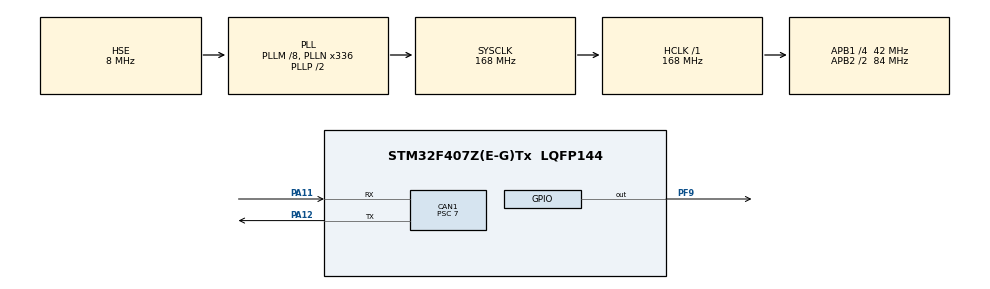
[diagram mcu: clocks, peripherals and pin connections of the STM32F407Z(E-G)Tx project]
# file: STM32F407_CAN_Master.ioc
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CAN1.BS1=CAN_BS1_7TQ
CAN1.BS2=CAN_BS2_4TQ
CAN1.CalculateBaudRate=499999
CAN1.CalculateTimeBit=2000
CAN1.CalculateTimeQuantum=166.66666666666669
CAN1.Prescaler=7
Mcu.Family=STM32F4
Mcu.Name=STM32F407Z(E-G)Tx
Mcu.Package=LQFP144
NVIC.CAN1_RX0_IRQn=true\:0\:0\:false\:false\:true\:true\:true\:true
NVIC.PriorityGroup=NVIC_PRIORITYGROUP_4
PA11.Mode=CAN_Activate
PA11.Signal=CAN1_RX
PA12.Mode=CAN_Activate
PA12.Signal=CAN1_TX
PA13.Mode=Serial_Wire
PA13.Signal=SYS_JTMS-SWDIO
PA14.Mode=Serial_Wire
PA14.Signal=SYS_JTCK-SWCLK
PF9.PinState=GPIO_PIN_SET
PF9.Signal=GPIO_Output
PH0-OSC_IN.Mode=HSE-External-Oscillator
PH0-OSC_IN.Signal=RCC_OSC_IN
PH1-OSC_OUT.Mode=HSE-External-Oscillator
PH1-OSC_OUT.Signal=RCC_OSC_OUT
ProjectManager.HeapSize=0x200
ProjectManager.StackSize=0x400
ProjectManager.TargetToolchain=MDK-ARM V5.32
RCC.48MHZClocksFreq_Value=84000000
RCC.AHBFreq_Value=168000000
RCC.APB1CLKDivider=RCC_HCLK_DIV4
RCC.APB1Freq_Value=42000000
RCC.APB1TimFreq_Value=84000000
RCC.APB2CLKDivider=RCC_HCLK_DIV2
RCC.APB2Freq_Value=84000000
RCC.APB2TimFreq_Value=168000000
RCC.CortexFreq_Value=168000000
RCC.HCLKFreq_Value=168000000
RCC.HSE_VALUE=8000000
RCC.HSI_VALUE=16000000
RCC.LSE_VALUE=32768
RCC.PLLM=8
RCC.PLLN=336
RCC.PLLSourceVirtual=RCC_PLLSOURCE_HSE
RCC.SYSCLKFreq_VALUE=168000000
RCC.SYSCLKSource=RCC_SYSCLKSOURCE_PLLCLK
RCC.VCOOutputFreq_Value=336000000
board=custom

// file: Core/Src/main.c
/* USER CODE BEGIN Header */
/**
  ******************************************************************************
  * @file           : main.c
  * @brief          : Main program body
  ******************************************************************************
  * @attention
  *
  * Copyright (c) 2026 STMicroelectronics.
  * All rights reserved.
  *
  * This software is licensed under terms that can be found in the LICENSE file
  * in the root directory of this software component.
  * If no LICENSE file comes with this software, it is provided AS-IS.
  *
  ******************************************************************************
  */
/* USER CODE END Header */
#include "main.h"
#include "can.h"
#include "gpio.h"
/* USER CODE BEGIN Includes */
#include "CO_driver.h"
#include "CANopen.h"
#include "OD.h"
/* USER CODE END Includes */

/* USER CODE BEGIN PV */
CO_t* CO = NULL;
/* USER CODE END PV */

void SystemClock_Config(void);

int main(void)
{

  /* MCU Configuration--------------------------------------------------------*/

  /* Reset of all peripherals, Initializes the Flash interface and the Systick. */
  HAL_Init();

  /* Configure the system clock */
  SystemClock_Config();

  /* Initialize all configured peripherals */
  MX_GPIO_Init();
  MX_CAN1_Init();
  /* USER CODE BEGIN 2 */
  HAL_CAN_Start(&hcan1); /* 启动CAN：退出初始化模式，进入正常模式 */
  /* USER CODE END 2 */

  /* Infinite loop */
  while (1)
  {

    /* USER CODE BEGIN 3 */

  /* 暂时不跑 CANopen，改用裸 CAN 发目标位置给 F103 */
  static uint32_t master_target = 16384;  // 第一个目标：90 度
  static uint32_t last_switch = 0;

  /* 每 3 秒切换目标，切换时只发一次（避免反复发打断 F103 定位） */
  if (HAL_GetTick() - last_switch > 3000) {
      last_switch = HAL_GetTick();
      master_target = (master_target == 16384) ? 32768 : 16384;

      uint8_t pos_data[4];
      pos_data[0] = (master_target >> 24) & 0xFF;  // 大端
      pos_data[1] = (master_target >> 16) & 0xFF;
      pos_data[2] = (master_target >> 8) & 0xFF;
      pos_data[3] = master_target & 0xFF;

      CAN_TxHeaderTypeDef tx_header;
      tx_header.StdId = 0x181;            // F103 收这个 ID
      tx_header.ExtId = 0;
      tx_header.IDE = CAN_ID_STD;
      tx_header.RTR = CAN_RTR_DATA;
      tx_header.DLC = 4;
      tx_header.TransmitGlobalTime = DISABLE;

      uint32_t tx_mailbox;
      HAL_CAN_AddTxMessage(&hcan1, &tx_header, pos_data, &tx_mailbox);
  }

  HAL_Delay(50);

  }

  /* USER CODE END 3 */
}

void SystemClock_Config(void)
{
  RCC_OscInitTypeDef RCC_OscInitStruct = {0};  /* RCC振荡器初始化结构体 */
  RCC_ClkInitTypeDef RCC_ClkInitStruct = {0};  /* RCC时钟初始化结构体 */

  /** Configure the main internal regulator output voltage
  */
  __HAL_RCC_PWR_CLK_ENABLE();
  __HAL_PWR_VOLTAGESCALING_CONFIG(PWR_REGULATOR_VOLTAGE_SCALE1);

  /** Initializes the RCC Oscillators according to the specified parameters
  * in the RCC_OscInitTypeDef structure.
  */
  RCC_OscInitStruct.OscillatorType = RCC_OSCILLATORTYPE_HSE;  /* RCC振荡器类型 */
  RCC_OscInitStruct.HSEState = RCC_HSE_ON;  /* RCC HSE 状态 */
  RCC_OscInitStruct.PLL.PLLState = RCC_PLL_ON;  /* RCC PLL 状态 */
  RCC_OscInitStruct.PLL.PLLSource = RCC_PLLSOURCE_HSE;  /* RCC PLL 源选择 */
  RCC_OscInitStruct.PLL.PLLM = 8;  /* RCC PLL 分频因子M */
  RCC_OscInitStruct.PLL.PLLN = 336;  /* RCC PLL 分频因子N */
  RCC_OscInitStruct.PLL.PLLP = RCC_PLLP_DIV2;  /* RCC PLL 分频因子P */
  RCC_OscInitStruct.PLL.PLLQ = 4;  /* RCC PLL 分频因子Q */
  if (HAL_RCC_OscConfig(&RCC_OscInitStruct) != HAL_OK)    /* 如果配置失败 */
  {
    Error_Handler();  /* 错误处理 */
  }

  /** Initializes the CPU, AHB and APB buses clocks
  */
  RCC_ClkInitStruct.ClockType = RCC_CLOCKTYPE_HCLK|RCC_CLOCKTYPE_SYSCLK  /* RCC时钟类型 */
                              |RCC_CLOCKTYPE_PCLK1|RCC_CLOCKTYPE_PCLK2;  /* RCC时钟类型 */
  RCC_ClkInitStruct.SYSCLKSource = RCC_SYSCLKSOURCE_PLLCLK;  /* RCC时钟源 */
  RCC_ClkInitStruct.AHBCLKDivider = RCC_SYSCLK_DIV1;  /* RCC时钟分频因子 */
  RCC_ClkInitStruct.APB1CLKDivider = RCC_HCLK_DIV4;  /* RCC时钟分频因子 */
  RCC_ClkInitStruct.APB2CLKDivider = RCC_HCLK_DIV2;  /* RCC时钟分频因子 */

  if (HAL_RCC_ClockConfig(&RCC_ClkInitStruct, FLASH_LATENCY_5) != HAL_OK)    /* 如果配置失败 */
  {
    Error_Handler();  /* 错误处理 */
  }
}

/* USER CODE BEGIN 4 */
void HAL_CAN_RxFifo0MsgPendingCallback(CAN_HandleTypeDef* hcan) {
  if(CO != NULL && CO->CANmodule != NULL) {
    CO_CANinterrupt(CO->CANmodule); /* 处理CAN中断 */
  }
}
/* USER CODE END 4 */

void Error_Handler(void)  /* 错误处理函数 */
{
  /* USER CODE BEGIN Error_Handler_Debug */
  /* User can add his own implementation to report the HAL error return state */
  __disable_irq();  /* 禁用中断 */
  while (1)  /* 无限循环 */
  {
  }
  /* USER CODE END Error_Handler_Debug */
}
